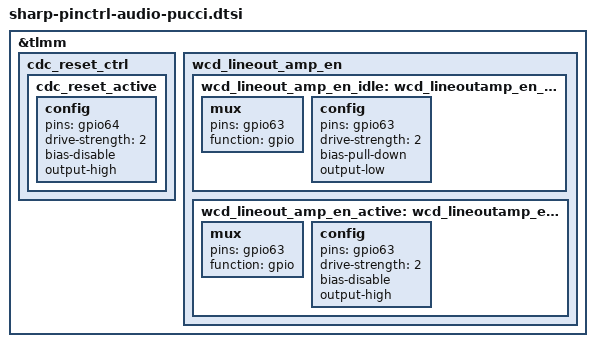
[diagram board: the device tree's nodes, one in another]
/* Copyright (c) 2016, The Linux Foundation. All rights reserved.
 *
 * This program is free software; you can redistribute it and/or modify
 * it under the terms of the GNU General Public License version 2 and
 * only version 2 as published by the Free Software Foundation.
 *
 * This program is distributed in the hope that it will be useful,
 * but WITHOUT ANY WARRANTY; without even the implied warranty of
 * MERCHANTABILITY or FITNESS FOR A PARTICULAR PURPOSE.  See the
 * GNU General Public License for more details.
 */
/* SH_AUDIO_DRIVER -> */ /*A-001*/
&tlmm{
	cdc_reset_ctrl {
		cdc_reset_active:cdc_reset_active {
			config {
				pins = "gpio64";
				drive-strength = <2>;
				bias-disable;
				output-high;
			};
		};
	};

	wcd_lineout_amp_en {
		wcd_lineout_amp_en_idle: wcd_lineoutamp_en_idle {
			mux {
				pins = "gpio63";
				function = "gpio";
			};
			config {
				pins = "gpio63";
				drive-strength = <2>;
				bias-pull-down;
				output-low;
			};
		};
		wcd_lineout_amp_en_active: wcd_lineoutamp_en_active {
			mux {
				pins = "gpio63";
				function = "gpio";
			};
			config {
				pins = "gpio63";
				drive-strength = <2>;
				bias-disable;
				output-high;
			};
		};
	};
};
/* SH_AUDIO_DRIVER <- */ /*A-001*/
